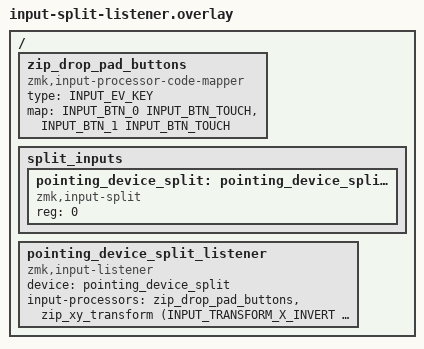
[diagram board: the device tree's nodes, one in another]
#include <zephyr/dt-bindings/input/input-event-codes.h>
#include <dt-bindings/zmk/input_transform.h>

/{
    /* パッドのタップ (BTN_0/BTN_1) を ZMK が無視するコードへ付け替え、
       ボタン参照カウントを触らせない。クリックはキーの &mkp で行う */
    zip_drop_pad_buttons: zip_drop_pad_buttons {
        compatible = "zmk,input-processor-code-mapper";
        #input-processor-cells = <0>;
        type = <INPUT_EV_KEY>;
        map = <INPUT_BTN_0 INPUT_BTN_TOUCH>
            , <INPUT_BTN_1 INPUT_BTN_TOUCH>;
    };

    split_inputs {
        #address-cells = <1>;
        #size-cells = <0>;

        pointing_device_split: pointing_device_split@0 {
            compatible = "zmk,input-split";
            reg = <0>;
        };
    };

    pointing_device_split_listener: pointing_device_split_listener {
        compatible = "zmk,input-listener";
        device = <&pointing_device_split>;
        status = "okay";
        input-processors = <&zip_drop_pad_buttons>,
                           <&zip_xy_transform (INPUT_TRANSFORM_X_INVERT | INPUT_TRANSFORM_Y_INVERT)>;
    };
};
